# MM32F3270 register map
File version: 3.01
CPU: CM3 r2p1, selectable endian, MPU, no FPU, 3 interrupt priority bits
Registers are 32-bit, read-write, reset 0x0 unless marked. A register's access mark holds for its fields unless they carry their own. Offsets are from the block's base; [hi:lo] are bit positions; {n}, {i} and the like mark numbered series.

## BKP — Backup registers
Base 0x40002840
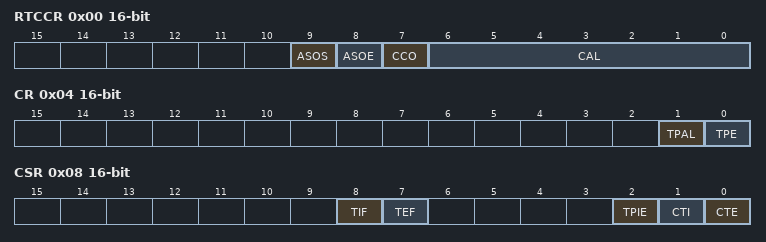
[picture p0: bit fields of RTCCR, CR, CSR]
0x00 RTCCR 16-bit — RTC clock calibration register
  [9] ASOS — Alarm or second output selection
  [8] ASOE — Alarm or second output enable
  [7] CCO — Calibration clock output
  [6:0] CAL — Calibration value
0x04 CR 16-bit — Backup control register
  [1] TPAL — TAMPER pin active level
  [0] TPE — TAMPER pin enable
0x08 CSR 16-bit — BKP control/status register
  [8] TIF ro — Tamper interrupt flag
  [7] TEF ro — Tamper event flag
  [2] TPIE — TAMPER pin interrupt enable
  [1] CTI wo — Clear tamper interrupt
  [0] CTE wo — Clear tamper event
{0xC+4i} DR{i} (i=1..20) — Backup data register(BKP_DR)
  [15:0] BKP — Backup data

## CACHE
Base 0x40016000
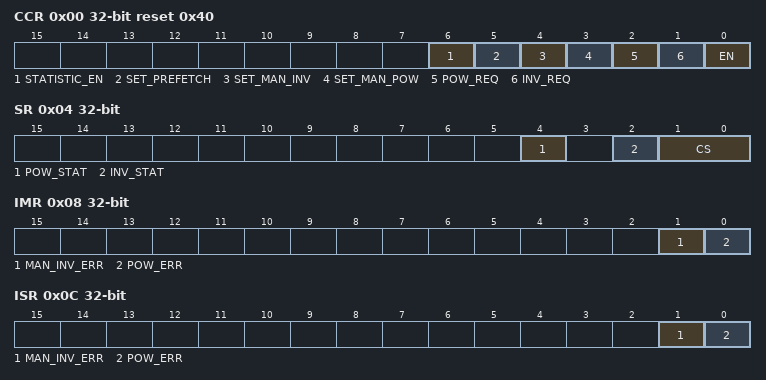
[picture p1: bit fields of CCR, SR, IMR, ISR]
0x00 CCR reset 0x40 — Configuration and control register
  [6] STATISTIC_EN — Enable statistics
  [5] SET_PREFETCH — Prefetch value
  [4] SET_MAN_INV — Set manual or automatic invalid
  [3] SET_MAN_POW — Set manual or automatic SRAM power request
  [2] POW_REQ — Manual SRAM power request
  [1] INV_REQ — Invalid manual set request
  [0] EN — Enable cache
0x04 SR ro — status register
  [4] POW_STAT — SRAM power response
  [2] INV_STAT — Invalid status
  [1:0] CS — Cache status
0x08 IMR — Interrupt mask register
  [1] MAN_INV_ERR — Invalid manual error interrupt request mask
  [0] POW_ERR — Power error interrupt request mask
0x0C ISR — Interrupt status register
  [1] MAN_INV_ERR — Invalid manual error flag
  [0] POW_ERR — Manual power error flag
0x14 CSHR — Cache statistics hit register
  [31:0] CSHR — hit statistics
0x18 CSMR — Cache statistics miss register
  [31:0] CSMR — miss statistics

## COMP — Comparator
Base 0x40014000
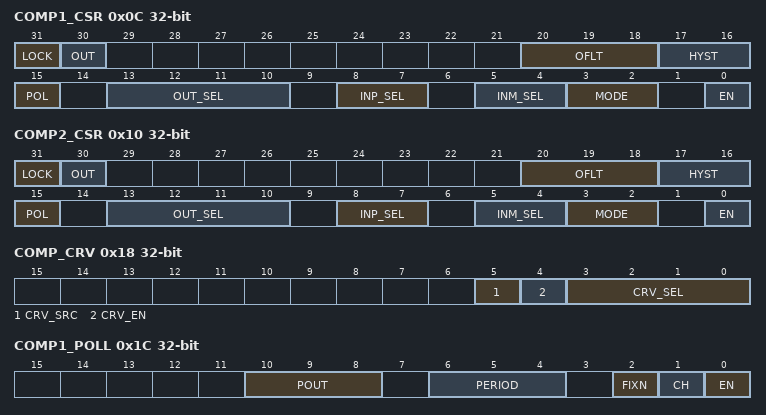
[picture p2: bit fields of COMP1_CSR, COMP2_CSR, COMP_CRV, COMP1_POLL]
0x0C COMP1_CSR — COMP1 Control State Register
  [31] LOCK — Comparator 1 lock
  [30] OUT ro — Comparator 1 output status
  [20:18] OFLT — Comparator 1 output filter
  [17:16] HYST — Comparator 1 hysteresis
  [15] POL — Comparator 1 output polarity
  [13:10] OUT_SEL — Comparator 1 output selection
  [8:7] INP_SEL — Comparator 1 normal phase input selection
  [5:4] INM_SEL — Comparator 1 inverting input selection
  [3:2] MODE — Comparator 1 mode
  [0] EN — Comparator 1 enable
0x10 COMP2_CSR — COMP2 Control State Register
  [31] LOCK — Comparator 2 lock
  [30] OUT ro — Comparator 2 output status
  [20:18] OFLT — Comparator 2 output filter
  [17:16] HYST — Comparator 2 hysteresis
  [15] POL — Comparator 2 output polarity
  [13:10] OUT_SEL — Comparator 2 output selection
  [8:7] INP_SEL — Comparator 2 normal phase input selection
  [5:4] INM_SEL — Comparator 2 inverting input selection
  [3:2] MODE — Comparator 2 mode
  [0] EN — Comparator 2 enable
0x18 COMP_CRV — COMP Extern Reference Voltage
  [5] CRV_SRC — Comparator external reference voltage source select
  [4] CRV_EN — Comparator external reference voltage enable
  [3:0] CRV_SEL — Comparator external reference voltage select
0x1C COMP1_POLL — COMP1 Polling Output Register
  [10:8] POUT ro — Comparator 1 Polling output
  [6:4] PERIOD — Comparator 1 polling wait cycle
  [2] FIXN — Comparator 1 Polling inverting input fix
  [1] CH — Comparator 1 polling channel
  [0] EN — Comparator 1 polling enable
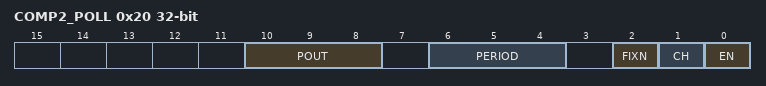
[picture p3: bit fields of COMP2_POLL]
0x20 COMP2_POLL — COMP2 Polling Output Register
  [10:8] POUT ro — Comparator 2 Polling output
  [6:4] PERIOD — Comparator 2 polling wait cycle
  [2] FIXN — Comparator 2 Polling inverting input fix
  [1] CH — Comparator 2 polling channel
  [0] EN — Comparator 2 polling enable

## CRC — CRC calculation unit
Base 0x40023000
0x00 DR reset 0xFFFFFFFF — Data register
  [31:0] DR — Data register bits
0x04 IDR — Independent data register
  [7:0] IDR — General-purpose 8-bit data register bits
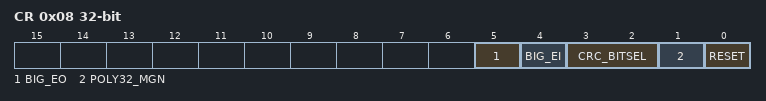
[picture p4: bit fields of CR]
0x08 CR — Control register
  [5] BIG_EO — Output big or small selection
  [4] BIG_EI — Input big or small selection
  [3:2] CRC_BITSEL — Input bit selection
  [1] POLY32_MGN — CRC algorithm selection
  [0] RESET wo — CRC reset
0x0C MIR reset 0xFFFFFFFF — Middle data register
